# GD32F10x_XD register map
File version: 1.0
CPU: CM3 r2p1, little endian, no MPU, no FPU, 4 interrupt priority bits
Registers are 32-bit, read-write, reset 0x0 unless marked. A register's access mark holds for its fields unless they carry their own. Offsets are from the block's base; [hi:lo] are bit positions; {n}, {i} and the like mark numbered series.

## AFIO — Alternate-function I/Os
Base 0x40010000
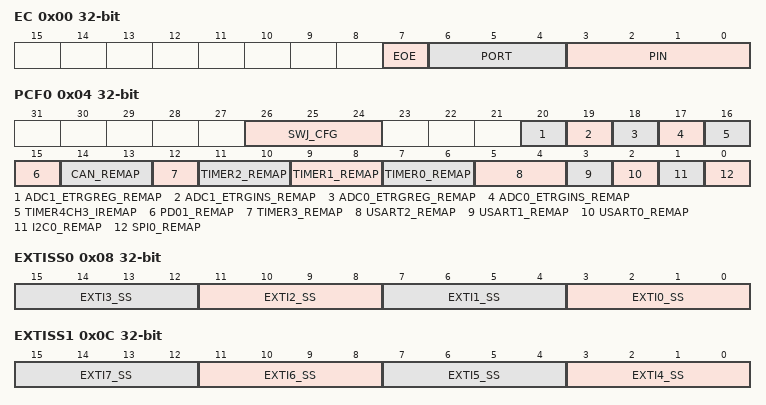
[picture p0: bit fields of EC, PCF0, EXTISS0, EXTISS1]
0x00 EC — Event control register
  [7] EOE — Event output enable
  [6:4] PORT — Event output port selection
  [3:0] PIN — Event output pin selection
0x04 PCF0 — AFIO port configuration register 0
  [26:24] SWJ_CFG — Serial wire JTAG configuration
  [20] ADC1_ETRGREG_REMAP — ADC1 external trigger regular conversion remapping
  [19] ADC1_ETRGINS_REMAP — ADC1 external trigger inserted conversion remapping
  [18] ADC0_ETRGREG_REMAP — ADC0 external trigger regular conversion remapping
  [17] ADC0_ETRGINS_REMAP — ADC0 external trigger inserted conversion remapping
  [16] TIMER4CH3_IREMAP — TIMER4 channel3 internal remapping
  [15] PD01_REMAP — Port D0/Port D1 mapping on OSC_IN/OSC_OUT
  [14:13] CAN_REMAP — CAN alternate interface remapping
  [12] TIMER3_REMAP — TIMER3 remapping
  [11:10] TIMER2_REMAP — TIMER2 remapping
  [9:8] TIMER1_REMAP — TIMER1 remapping
  [7:6] TIMER0_REMAP — TIMER0 remapping
  [5:4] USART2_REMAP — USART2 remapping
  [3] USART1_REMAP — USART1 remapping
  [2] USART0_REMAP — USART0 remapping
  [1] I2C0_REMAP — I2C0 remapping
  [0] SPI0_REMAP — SPI0 remapping
0x08 EXTISS0 — EXTI sources selection register 0
  [4n+3:4n] EXTI{n}_SS (n=0..3) — EXTI {n} sources selection
0x0C EXTISS1 — EXTI sources selection register 1
  [4n-13:4n-16] EXTI{n}_SS (n=4..7) — EXTI {n} sources selection
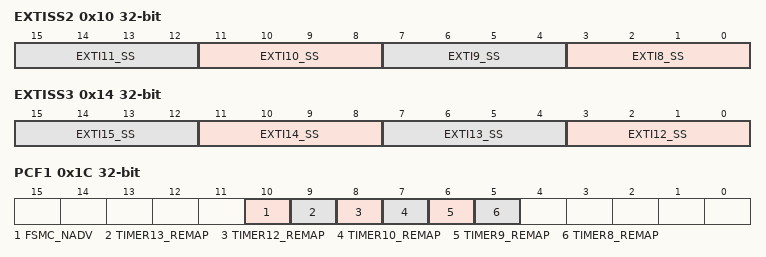
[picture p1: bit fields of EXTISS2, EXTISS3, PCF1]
0x10 EXTISS2 — EXTI sources selection register 2
  [4n-29:4n-32] EXTI{n}_SS (n=8..11) — EXTI {n} sources selection
0x14 EXTISS3 — EXTI sources selection register 3
  [4n-45:4n-48] EXTI{n}_SS (n=12..15) — EXTI {n} sources selection
0x1C PCF1 — AFIO port configuration register 1
  [10] FSMC_NADV — FSMC_NADV connect/disconnect
  [9] TIMER13_REMAP — TIMER13 remapping
  [8] TIMER12_REMAP — TIMER12 remapping
  [7] TIMER10_REMAP — TIMER10 remapping
  [6] TIMER9_REMAP — TIMER9 remapping
  [5] TIMER8_REMAP — TIMER8 remapping

## BKP — Backup registers
Base 0x40006C00
{0x4+4i} DATA{i} (i=0..9) — Backup data register {i}
  [15:0] DATA — Backup data
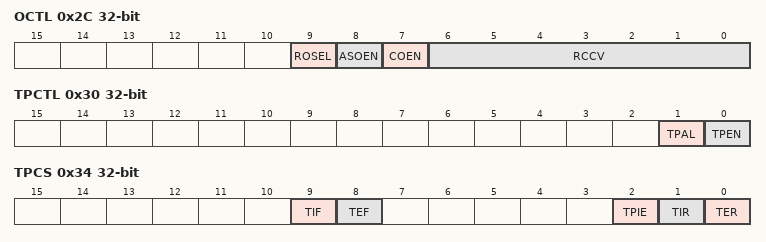
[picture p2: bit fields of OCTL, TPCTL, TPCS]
0x2C OCTL — RTC signal output control register
  [9] ROSEL — RTC output selection
  [8] ASOEN — RTC alarm or second signal output enable
  [7] COEN — RTC clock calibration output enable
  [6:0] RCCV — RTC clock calibration value
0x30 TPCTL — Tamper pin control register
  [1] TPAL — TAMPER pin active level
  [0] TPEN — TAMPER detection enable
0x34 TPCS — Tamper control and status register
  [9] TIF — Tamper interrupt flag
  [8] TEF — Tamper event flag
  [2] TPIE — Tamper interrupt enable
  [1] TIR — Tamper interrupt reset
  [0] TER — Tamper event reset
{0x18+4i} DATA{i} (i=10..41) — Backup data register {i}
  [15:0] DATA — Backup data

## CRC — cyclic redundancy check calculation unit
Base 0x40023000
0x00 DATA reset 0xFFFFFFFF
  [31:0] DATA — CRC calculation result bits
0x04 FDATA — Free data register
  [7:0] FDATA — Free Data Register bits
0x08 CTL — Control register
  [0] RST — reset bit

## DAC — Digital-to-analog converter
Base 0x40007400
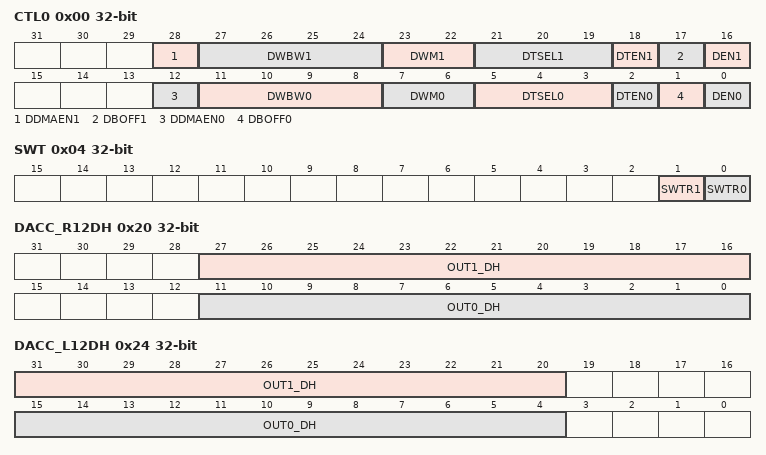
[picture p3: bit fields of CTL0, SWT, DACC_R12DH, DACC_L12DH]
0x00 CTL0 — DACx control register 0
  [28] DDMAEN1 — DACx_OUT1 DMA enable
  [27:24] DWBW1 — DACx_OUT1 noise wave bit width
  [23:22] DWM1 — DACx_OUT1 noise wave mode
  [21:19] DTSEL1 — DACx_OUT1 trigger selection
  [18] DTEN1 — DACx_OUT1 trigger enable
  [17] DBOFF1 — DACx_OUT1 output buffer turn off
  [16] DEN1 — DACx_OUT1 enable
  [12] DDMAEN0 — DACx_OUT0 DMA enable
  [11:8] DWBW0 — DACx_OUT0 noise wave bit width
  [7:6] DWM0 — DACx_OUT0 noise wave mode
  [5:3] DTSEL0 — DACx_OUT0 trigger selection
  [2] DTEN0 — DACx_OUT0 trigger enable
  [1] DBOFF0 — DACx_OUT0 output buffer turn off
  [0] DEN0 — DACx_OUT0 enable
0x04 SWT wo — DACx software trigger register
  [1] SWTR1 — DACx_OUT1 software trigger, cleared by hardware.
  [0] SWTR0 — DACx_OUT0 software trigger, cleared by hardware.
0x08 OUT0_R12DH — DACx_OUT0 12-bit right-aligned data holding register
  [11:0] OUT0_DH — DACx_OUT0 12-bit right-aligned data.
0x0C OUT0_L12DH — DACx_OUT0 12-bit left-aligned data holding register
  [15:4] OUT0_DH — DACx_OUT0 12-bit left-aligned data.
0x10 OUT0_R8DH — DACx_OUT0 8-bit right-aligned data holding register
  [7:0] OUT0_DH — DACx_OUT0 8-bit right-aligned data.
0x14 OUT1_R12DH — DACx_OUT1 12-bit right-aligned data holding register
  [11:0] OUT1_DH — DACx_OUT1 12-bit right-aligned data.
0x18 OUT1_L12DH — DACx_OUT1 12-bit left-aligned data holding register
  [15:4] OUT1_DH — DACx_OUT1 12-bit left-aligned data.
0x1C OUT1_R8DH — DACx_OUT1 8-bit right-aligned data holding register
  [7:0] OUT1_DH — DACx_OUT1 8-bit right-aligned data
0x20 DACC_R12DH — DACx concurrent mode 12-bit right-aligned data holding register
  [27:16] OUT1_DH — DACx_OUT1 12-bit right-aligned data
  [11:0] OUT0_DH — DACx_OUT0 12-bit right-aligned data
0x24 DACC_L12DH — DACx concurrent mode 12-bit left-aligned data holding register
  [31:20] OUT1_DH — DACx_OUT1 12-bit left-aligned data
  [15:4] OUT0_DH — DACx_OUT0 12-bit left-aligned data
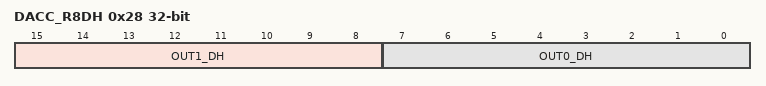
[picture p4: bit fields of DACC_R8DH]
0x28 DACC_R8DH — DACx concurrent mode 8-bit right-aligned data holding register
  [15:8] OUT1_DH — DACx_OUT1 8-bit right-aligned data
  [7:0] OUT0_DH — DACx_OUT0 8-bit right-aligned data
0x2C OUT0_DO ro — DACx_OUT0 data output register
  [11:0] OUT0_DO — DACx_OUT0 12-bit output data
0x30 OUT1_DO ro — DACx_OUT1 data output register
  [11:0] OUT1_DO — DACx_OUT1 12-bit output data
